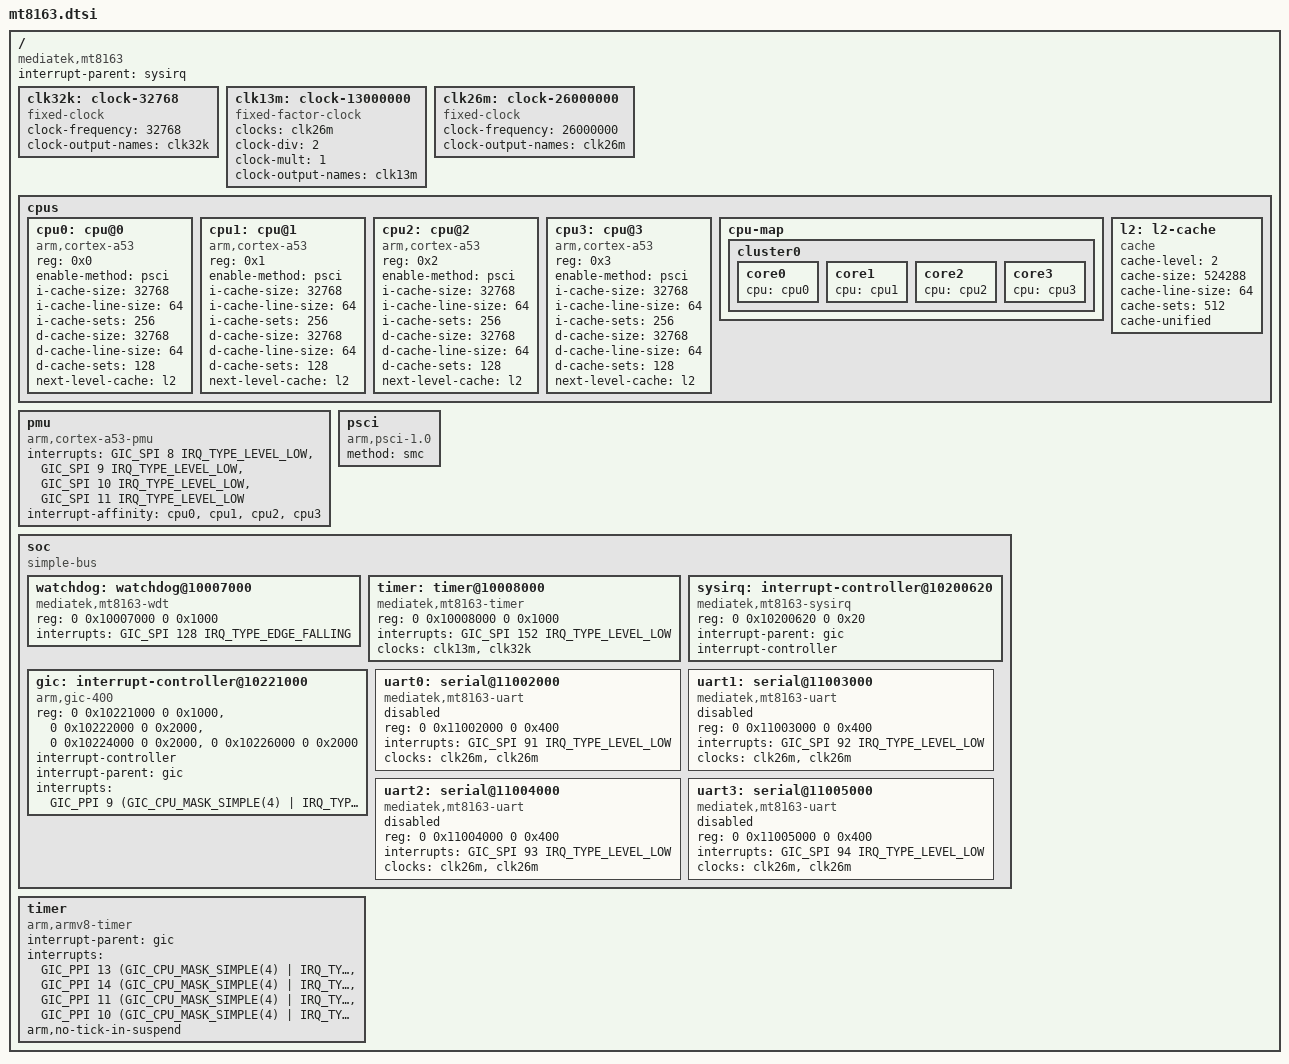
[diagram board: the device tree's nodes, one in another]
// SPDX-License-Identifier: GPL-2.0-only OR MIT
/*
 * Copyright (c) 2026 Ben Grisdale <bengris32@protonmail.ch>
 */

#include <dt-bindings/interrupt-controller/arm-gic.h>

/ {
	compatible = "mediatek,mt8163";
	interrupt-parent = <&sysirq>;
	#address-cells = <2>;
	#size-cells = <2>;

	clk32k: clock-32768 {
		compatible = "fixed-clock";
		#clock-cells = <0>;
		clock-frequency = <32768>;
		clock-output-names = "clk32k";
	};

	clk13m: clock-13000000 {
		compatible = "fixed-factor-clock";
		#clock-cells = <0>;
		clocks = <&clk26m>;
		clock-div = <2>;
		clock-mult = <1>;
		clock-output-names = "clk13m";
	};

	clk26m: clock-26000000 {
		compatible = "fixed-clock";
		#clock-cells = <0>;
		clock-frequency = <26000000>;
		clock-output-names = "clk26m";
	};

	cpus {
		#address-cells = <1>;
		#size-cells = <0>;

		cpu0: cpu@0 {
			device_type = "cpu";
			compatible = "arm,cortex-a53";
			reg = <0x0>;
			enable-method = "psci";
			i-cache-size = <32768>;
			i-cache-line-size = <64>;
			i-cache-sets = <256>;
			d-cache-size = <32768>;
			d-cache-line-size = <64>;
			d-cache-sets = <128>;
			next-level-cache = <&l2>;
		};

		cpu1: cpu@1 {
			device_type = "cpu";
			compatible = "arm,cortex-a53";
			reg = <0x1>;
			enable-method = "psci";
			i-cache-size = <32768>;
			i-cache-line-size = <64>;
			i-cache-sets = <256>;
			d-cache-size = <32768>;
			d-cache-line-size = <64>;
			d-cache-sets = <128>;
			next-level-cache = <&l2>;
		};

		cpu2: cpu@2 {
			device_type = "cpu";
			compatible = "arm,cortex-a53";
			reg = <0x2>;
			enable-method = "psci";
			i-cache-size = <32768>;
			i-cache-line-size = <64>;
			i-cache-sets = <256>;
			d-cache-size = <32768>;
			d-cache-line-size = <64>;
			d-cache-sets = <128>;
			next-level-cache = <&l2>;
		};

		cpu3: cpu@3 {
			device_type = "cpu";
			compatible = "arm,cortex-a53";
			reg = <0x3>;
			enable-method = "psci";
			i-cache-size = <32768>;
			i-cache-line-size = <64>;
			i-cache-sets = <256>;
			d-cache-size = <32768>;
			d-cache-line-size = <64>;
			d-cache-sets = <128>;
			next-level-cache = <&l2>;
		};

		cpu-map {
			cluster0 {
				core0 {
					cpu = <&cpu0>;
				};

				core1 {
					cpu = <&cpu1>;
				};

				core2 {
					cpu = <&cpu2>;
				};

				core3 {
					cpu = <&cpu3>;
				};
			};
		};

		l2: l2-cache {
			compatible = "cache";
			cache-level = <2>;
			cache-size = <524288>;
			cache-line-size = <64>;
			cache-sets = <512>;
			cache-unified;
		};
	};

	pmu {
		compatible = "arm,cortex-a53-pmu";
		interrupts = <GIC_SPI 8 IRQ_TYPE_LEVEL_LOW>,
			     <GIC_SPI 9 IRQ_TYPE_LEVEL_LOW>,
			     <GIC_SPI 10 IRQ_TYPE_LEVEL_LOW>,
			     <GIC_SPI 11 IRQ_TYPE_LEVEL_LOW>;
		interrupt-affinity = <&cpu0>, <&cpu1>, <&cpu2>, <&cpu3>;
	};

	psci {
		compatible = "arm,psci-1.0";
		method = "smc";
	};

	soc {
		compatible = "simple-bus";
		ranges;
		#address-cells = <2>;
		#size-cells = <2>;

		watchdog: watchdog@10007000 {
			compatible = "mediatek,mt8163-wdt";
			reg = <0 0x10007000 0 0x1000>;
			interrupts = <GIC_SPI 128 IRQ_TYPE_EDGE_FALLING>;
			#reset-cells = <1>;
		};

		timer: timer@10008000 {
			compatible = "mediatek,mt8163-timer",
				     "mediatek,mt6577-timer";
			reg = <0 0x10008000 0 0x1000>;
			interrupts = <GIC_SPI 152 IRQ_TYPE_LEVEL_LOW>;
			clocks = <&clk13m>, <&clk32k>;
			clock-names = "system-clk", "rtc-clk";
		};

		sysirq: interrupt-controller@10200620 {
			compatible = "mediatek,mt8163-sysirq",
				     "mediatek,mt6577-sysirq";
			reg = <0 0x10200620 0 0x20>;
			#interrupt-cells = <3>;
			interrupt-parent = <&gic>;
			interrupt-controller;
		};

		gic: interrupt-controller@10221000 {
			compatible = "arm,gic-400";
			reg = <0 0x10221000 0 0x1000>,
			      <0 0x10222000 0 0x2000>,
			      <0 0x10224000 0 0x2000>,
			      <0 0x10226000 0 0x2000>;
			interrupt-controller;
			#interrupt-cells = <3>;
			interrupt-parent = <&gic>;
			interrupts = <GIC_PPI 9 (GIC_CPU_MASK_SIMPLE(4) |
				      IRQ_TYPE_LEVEL_HIGH)>;
		};

		uart0: serial@11002000 {
			compatible = "mediatek,mt8163-uart",
				     "mediatek,mt6577-uart";
			reg = <0 0x11002000 0 0x400>;
			interrupts = <GIC_SPI 91 IRQ_TYPE_LEVEL_LOW>;
			clocks = <&clk26m>, <&clk26m>;
			clock-names = "baud", "bus";

			status = "disabled";
		};

		uart1: serial@11003000 {
			compatible = "mediatek,mt8163-uart",
				     "mediatek,mt6577-uart";
			reg = <0 0x11003000 0 0x400>;
			interrupts = <GIC_SPI 92 IRQ_TYPE_LEVEL_LOW>;
			clocks = <&clk26m>, <&clk26m>;
			clock-names = "baud", "bus";

			status = "disabled";
		};

		uart2: serial@11004000 {
			compatible = "mediatek,mt8163-uart",
				     "mediatek,mt6577-uart";
			reg = <0 0x11004000 0 0x400>;
			interrupts = <GIC_SPI 93 IRQ_TYPE_LEVEL_LOW>;
			clocks = <&clk26m>, <&clk26m>;
			clock-names = "baud", "bus";

			status = "disabled";
		};

		uart3: serial@11005000 {
			compatible = "mediatek,mt8163-uart",
				     "mediatek,mt6577-uart";
			reg = <0 0x11005000 0 0x400>;
			interrupts = <GIC_SPI 94 IRQ_TYPE_LEVEL_LOW>;
			clocks = <&clk26m>, <&clk26m>;
			clock-names = "baud", "bus";

			status = "disabled";
		};
	};

	timer {
		compatible = "arm,armv8-timer";
		interrupt-parent = <&gic>;
		interrupts = <GIC_PPI 13
			      (GIC_CPU_MASK_SIMPLE(4) | IRQ_TYPE_LEVEL_LOW)>,
			     <GIC_PPI 14
			      (GIC_CPU_MASK_SIMPLE(4) | IRQ_TYPE_LEVEL_LOW)>,
			     <GIC_PPI 11
			      (GIC_CPU_MASK_SIMPLE(4) | IRQ_TYPE_LEVEL_LOW)>,
			     <GIC_PPI 10
			      (GIC_CPU_MASK_SIMPLE(4) | IRQ_TYPE_LEVEL_LOW)>;
		arm,no-tick-in-suspend;
	};
};
